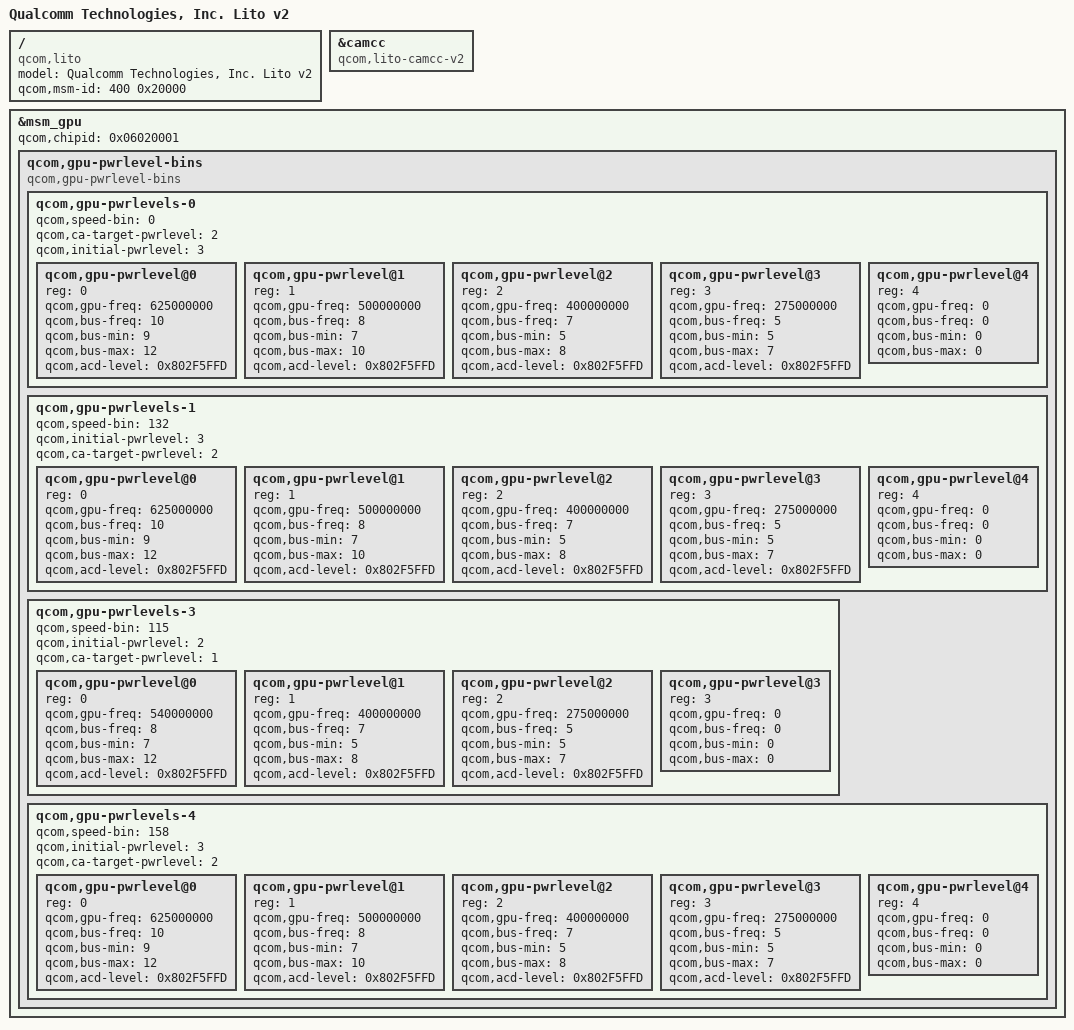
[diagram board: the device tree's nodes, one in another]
#include "lito.dtsi"

/ {
	model = "Qualcomm Technologies, Inc. Lito v2";
	compatible = "qcom,lito";
	qcom,msm-id = <400 0x20000>;
};

&camcc {
	compatible = "qcom,lito-camcc-v2";
};

&msm_gpu {
	/delete-property/qcom,chipid;
	qcom,chipid = <0x06020001>;

	/delete-node/qcom,gpu-pwrlevel-bins;
	qcom,gpu-pwrlevel-bins {
		#address-cells = <1>;
		#size-cells = <0>;

		compatible="qcom,gpu-pwrlevel-bins";

		qcom,gpu-pwrlevels-0 {
			#address-cells = <1>;
			#size-cells = <0>;

			qcom,speed-bin = <0>;
			qcom,ca-target-pwrlevel = <2>;
			qcom,initial-pwrlevel = <3>;

			/* NOM */
			qcom,gpu-pwrlevel@0 {
				reg = <0>;
				qcom,gpu-freq = <625000000>;
				qcom,bus-freq = <10>;
				qcom,bus-min = <9>;
				qcom,bus-max = <12>;
				qcom,acd-level = <0x802F5FFD>;
			};

			/* SVS L1 */
			qcom,gpu-pwrlevel@1 {
				reg = <1>;
				qcom,gpu-freq = <500000000>;
				qcom,bus-freq = <8>;
				qcom,bus-min = <7>;
				qcom,bus-max = <10>;
				qcom,acd-level = <0x802F5FFD>;
			};

			/* SVS */
			qcom,gpu-pwrlevel@2 {
				reg = <2>;
				qcom,gpu-freq = <400000000>;
				qcom,bus-freq = <7>;
				qcom,bus-min = <5>;
				qcom,bus-max = <8>;
				qcom,acd-level = <0x802F5FFD>;
			};

			/* Low SVS */
			qcom,gpu-pwrlevel@3 {
				reg = <3>;
				qcom,gpu-freq = <275000000>;
				qcom,bus-freq = <5>;
				qcom,bus-min = <5>;
				qcom,bus-max = <7>;
				qcom,acd-level = <0x802F5FFD>;
			};

			qcom,gpu-pwrlevel@4 {
				reg = <4>;
				qcom,gpu-freq = <0>;
				qcom,bus-freq = <0>;
				qcom,bus-min = <0>;
				qcom,bus-max = <0>;
			};
		};

		qcom,gpu-pwrlevels-1 {
			#address-cells = <1>;
			#size-cells = <0>;

			qcom,speed-bin = <132>;

			qcom,initial-pwrlevel = <3>;
			qcom,ca-target-pwrlevel = <2>;

			/* NOM */
			qcom,gpu-pwrlevel@0 {
				reg = <0>;
				qcom,gpu-freq = <625000000>;
				qcom,bus-freq = <10>;
				qcom,bus-min = <9>;
				qcom,bus-max = <12>;
				qcom,acd-level = <0x802F5FFD>;
			};

			/* SVS L1 */
			qcom,gpu-pwrlevel@1 {
				reg = <1>;
				qcom,gpu-freq = <500000000>;
				qcom,bus-freq = <8>;
				qcom,bus-min = <7>;
				qcom,bus-max = <10>;
				qcom,acd-level = <0x802F5FFD>;
			};

			/* SVS */
			qcom,gpu-pwrlevel@2 {
				reg = <2>;
				qcom,gpu-freq = <400000000>;
				qcom,bus-freq = <7>;
				qcom,bus-min = <5>;
				qcom,bus-max = <8>;
				qcom,acd-level = <0x802F5FFD>;
			};

			/* Low SVS */
			qcom,gpu-pwrlevel@3 {
				reg = <3>;
				qcom,gpu-freq = <275000000>;
				qcom,bus-freq = <5>;
				qcom,bus-min = <5>;
				qcom,bus-max = <7>;
				qcom,acd-level = <0x802F5FFD>;
			};

			qcom,gpu-pwrlevel@4 {
				reg = <4>;
				qcom,gpu-freq = <0>;
				qcom,bus-freq = <0>;
				qcom,bus-min = <0>;
				qcom,bus-max = <0>;
			};
		};

		qcom,gpu-pwrlevels-3 {
			#address-cells = <1>;
			#size-cells = <0>;

			qcom,speed-bin = <115>;
			qcom,initial-pwrlevel = <2>;
			qcom,ca-target-pwrlevel = <1>;

			/* SVS L1 */
			qcom,gpu-pwrlevel@0 {
				reg = <0>;
				qcom,gpu-freq = <540000000>;
				qcom,bus-freq = <8>;
				qcom,bus-min = <7>;
				qcom,bus-max = <12>;
				qcom,acd-level = <0x802F5FFD>;
			};

			/* SVS */
			qcom,gpu-pwrlevel@1 {
				reg = <1>;
				qcom,gpu-freq = <400000000>;
				qcom,bus-freq = <7>;
				qcom,bus-min = <5>;
				qcom,bus-max = <8>;
				qcom,acd-level = <0x802F5FFD>;
			};

			/* Low SVS */
			qcom,gpu-pwrlevel@2 {
				reg = <2>;
				qcom,gpu-freq = <275000000>;
				qcom,bus-freq = <5>;
				qcom,bus-min = <5>;
				qcom,bus-max = <7>;
				qcom,acd-level = <0x802F5FFD>;
			};

			qcom,gpu-pwrlevel@3 {
				reg = <3>;
				qcom,gpu-freq = <0>;
				qcom,bus-freq = <0>;
				qcom,bus-min = <0>;
				qcom,bus-max = <0>;
			};
		};

		qcom,gpu-pwrlevels-4 {
			#address-cells = <1>;
			#size-cells = <0>;

			qcom,speed-bin = <158>;

			qcom,initial-pwrlevel = <3>;
			qcom,ca-target-pwrlevel = <2>;

			/* NOM */
			qcom,gpu-pwrlevel@0 {
				reg = <0>;
				qcom,gpu-freq = <625000000>;
				qcom,bus-freq = <10>;
				qcom,bus-min = <9>;
				qcom,bus-max = <12>;
				qcom,acd-level = <0x802F5FFD>;
			};

			/* SVS L1 */
			qcom,gpu-pwrlevel@1 {
				reg = <1>;
				qcom,gpu-freq = <500000000>;
				qcom,bus-freq = <8>;
				qcom,bus-min = <7>;
				qcom,bus-max = <10>;
				qcom,acd-level = <0x802F5FFD>;
			};

			/* SVS */
			qcom,gpu-pwrlevel@2 {
				reg = <2>;
				qcom,gpu-freq = <400000000>;
				qcom,bus-freq = <7>;
				qcom,bus-min = <5>;
				qcom,bus-max = <8>;
				qcom,acd-level = <0x802F5FFD>;
			};

			/* Low SVS */
			qcom,gpu-pwrlevel@3 {
				reg = <3>;
				qcom,gpu-freq = <275000000>;
				qcom,bus-freq = <5>;
				qcom,bus-min = <5>;
				qcom,bus-max = <7>;
				qcom,acd-level = <0x802F5FFD>;
			};

			qcom,gpu-pwrlevel@4 {
				reg = <4>;
				qcom,gpu-freq = <0>;
				qcom,bus-freq = <0>;
				qcom,bus-min = <0>;
				qcom,bus-max = <0>;
			};
		};
	};
};
